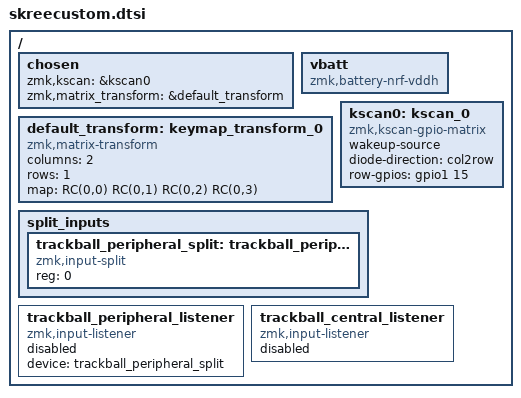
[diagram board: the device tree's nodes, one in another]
#include <dt-bindings/zmk/matrix_transform.h>
#include <input/processors.dtsi>
#include <dt-bindings/zmk/input_transform.h>

 / {
     chosen {
        zmk,kscan = &kscan0;
        zmk,matrix_transform = &default_transform;
    };

    vbatt: vbatt {
	compatible = "zmk,battery-nrf-vddh";
    };
 
     default_transform: keymap_transform_0 {
         compatible = "zmk,matrix-transform";
         columns = <2>;
         rows = <1>;

         map = <
        RC(0,0) RC(0,1)                     RC(0,2) RC(0,3)              

         >;
     };

     kscan0: kscan_0 {
        compatible = "zmk,kscan-gpio-matrix";
        wakeup-source;

        diode-direction = "col2row";
        row-gpios
             = <&gpio1 15 (GPIO_ACTIVE_HIGH | GPIO_PULL_DOWN)> //r1-7 1.15 0.28 1.01 0.09 0.10 1.11 1.07thumbs
//            , <&gpio0 28 (GPIO_ACTIVE_HIGH | GPIO_PULL_DOWN)> 
//            , <&gpio1 1 (GPIO_ACTIVE_HIGH | GPIO_PULL_DOWN)> 
//            , <&gpio0 9 (GPIO_ACTIVE_HIGH | GPIO_PULL_DOWN)> 
//            , <&gpio0 10 (GPIO_ACTIVE_HIGH | GPIO_PULL_DOWN)> 
//            , <&gpio1 11 (GPIO_ACTIVE_HIGH | GPIO_PULL_DOWN)> 
//            , <&gpio1 7 (GPIO_ACTIVE_HIGH | GPIO_PULL_DOWN)> 
            ;

    };


//right hand trackball
    split_inputs {
        #address-cells = <1>;
        #size-cells = <0>;

        trackball_peripheral_split: trackball_peripheral_split@0 {
            compatible = "zmk,input-split";
            reg = <0>;
        };
    };

    trackball_peripheral_listener: trackball_peripheral_listener {
        compatible = "zmk,input-listener";
        status = "disabled";
        device = <&trackball_peripheral_split>;
    };
//left hand trackball
    trackball_central_listener: trackball_central_listener {
        compatible = "zmk,input-listener";
        status = "disabled";
    };
};


//&spi0 {
//    status = "okay";
//    pinctrl-0 = <&spi0_default>;
//    pinctrl-1 = <&spi0_sleep>;
//    pinctrl-names = "default", "sleep";
//    cs-gpios = <&gpio1 13 GPIO_ACTIVE_LOW>;
//    shifter: 595@0 {
//        compatible = "zmk,gpio-595";
//        status = "okay";
//        gpio-controller;
//        spi-max-frequency = <200000>;
//        reg = <0>;
//        #gpio-cells = <2>;
//        ngpios = <8>;
//    };
//};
